# EVE1_VCOP register map
Vendor: Texas Instruments
Peripheral module from a debugger description file (folder DRA75x_DRA74x).
Registers are 32-bit, read-only, reset 0x0 unless marked. A register's access mark holds for its fields unless they carry their own. Offsets are as the file gives them; lines under a group give offsets from that group; [hi:lo] are bit positions; {n}, {i} and the like mark numbered series; 'fields as' and 'values as' point back to an identical list; <NAME> marks a mode.

## EVE1_VCOP
0x00 VCOP_PID
  [31:0] PID — IP Revision
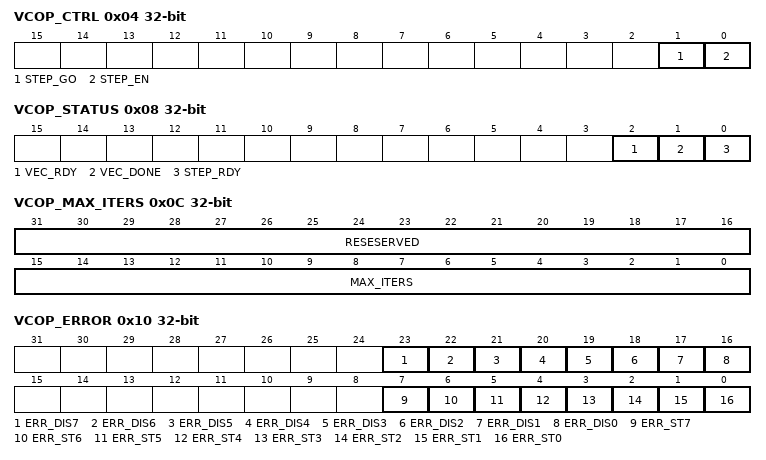
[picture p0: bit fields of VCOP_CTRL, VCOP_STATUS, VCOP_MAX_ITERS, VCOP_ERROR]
0x04 VCOP_CTRL access per field — VCOP Control Register
  [1] STEP_GO rw — Starts executing a single i4 iteration
    0=NOP; 1=START
  [0] STEP_EN rw — Enable Single Step mode
    0=Disable; 1=Enable
0x08 VCOP_STATUS
  [2] VEC_RDY — Vector core ready to accept next vector instruction
  [1] VEC_DONE — Vector core has completed execution of submitted vector loops.
  [0] STEP_RDY — Ready for next step (single step)
    0=Busy; 1=Idle_and_ready_for_next_step
0x0C VCOP_MAX_ITERS access per field
  [31:16] RESESERVED ro — Reserved. Read returns 0s
  [15:0] MAX_ITERS rw — Maximum iteration count. Send interrupt when a loop in execution exceeds the programmed max iteration count. This is to guard against VCOP hangs due to run-away program.
    0=Disable_(default); 1=Enable
0x10 VCOP_ERROR rw — Error interrupt enalbe and status register. Writing 1 to the ERR_STi bits clears the interrupt status.
  [23] ERR_DIS7 — Error Interrupt disable.
    0=Enable; 1=Disable_ST_PDDA_bank_conflict
  [22] ERR_DIS6 — Error Interrupt disable.
    0=Enable; 1=Disable_ST_WBUF_out-of-bound
  [21] ERR_DIS5 — Error Interrupt disable.
    0=Enable; 1=Disable_ST_IBUF_out-of-bound
  [20] ERR_DIS4 — Error Interrupt disable.
    0=Enable; 1=Disable_LD_WBUF_out-of-bound
  [19] ERR_DIS3 — Error Interrupt disable.
    0=Enable; 1=Disable_LD_IBUF_out-of-bound
  [18] ERR_DIS2 — Error Interrupt disable.
    0=Enable; 1=Disable Illegal parameter (pointer not 32-bit aligned, pointer out-of-bound, exceed max repeat count)
  [17] ERR_DIS1 — Error Interrupt disable.
    0=Enable; 1=Disable Illegal instruction, all other causes than inside-loop instructions detected outside loop
  [16] ERR_DIS0 — Error Interrupt disable.
    0=Enable; 1=VADD)_VCOP_PC_ARP32_PC_VLOOP_1 (Disable Illegal instruction; inside-loop instructions (eg, VADD) detected outside loop.When this occurs, the decode value is indeterminate, since VCOP expects valid PC on vec_paddr bus, and ARP32 only sends PC with valid VLOOP instruction.)
  [7] ERR_ST7 — ST_PDDA bank conflict error status:
    0=No_error; 1=Error
  [6] ERR_ST6 — ST WBUF out-of-bound error status:
    0=No_error; 1=Error
  [5] ERR_ST5 — ST IBUF out-of-bound error status:
    0=No_error; 1=Error
  [4] ERR_ST4 — LD WBUF out-of-bound error status:
    0=No_error; 1=Error
  [3] ERR_ST3 — LD IBUF out-of-bound error status:
    0=No_error; 1=Error
  [2] ERR_ST2 — Illegal parameter error status. Effected when pointer is not 32-bit aligned, pointer is outof- bound, or exceed max repeat count.
    0=No_error; 1=Error
  [1] ERR_ST1 — Illegal instruction error status. Effected by all other causes than inside-loop instructions detected outside loop.
    0=No_error; 1=Error
  [0] ERR_ST0 — Illegal instruction error status. Effected by inside-loop instructions (eg, VADD) detected outside loop. When this occurs, VCOP_VLOOP_PTR_DEC value is indeterminate, since VCOP expects valid PC on vec_paddr bus, and ARP32 only sends PC with valid VLOOP instruction.
    0=No_error; 1=Error
0x20 VCOP_VLOOP_PTR — The VLOOP pointer
  [31:0] VLOOP_PTR — VLOOP pointer.
0x24 VCOP_PARAM_PTR
  [31:0] PARAM_PTR — Points to the beginning of parameter block for the loop in execution.
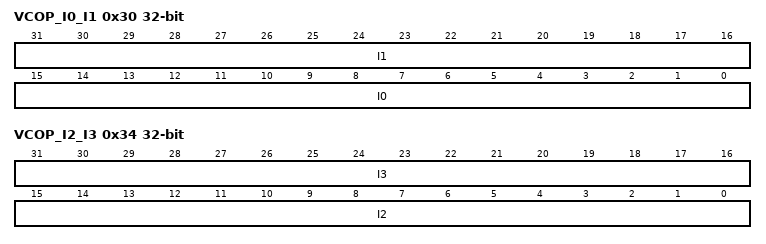
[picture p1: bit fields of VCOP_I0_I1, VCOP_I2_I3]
0x30 VCOP_I0_I1 — I0, I1 loop variables register provides a snapshot of i0 and i1
  [31:16] I1 — Snapshot of I1 loop variable.
  [15:0] I0 — Snapshot of I0 loop variable.
0x34 VCOP_I2_I3 — I2, I3 loop variables register provides a snapshot of i2 and i3
  [31:16] I3 — Snapshot of I2 loop variable.
  [15:0] I2 — Snapshot of I3 loop variable.
0x38 VCOP_I4 — I4 loop variables register provides a snapshot of i4
  [15:0] I4 — Snapshot of I4 loop variable.
{0x40+4i} VCOP_LD_PTR_i_{i} (i=0..7) — The LD pointer registers 0 to 7 or (VCOP_LD_PTR(0..7)) is a snapshot of the LD memory address. The LD unit is identified by the destination vector register V0..V7
  [31:0] LD_PTRi — LD pointer i (i = 0 to 7).
{0x60+4i} VCOP_ST_PTR_j_{i} (i=0..7) — The ST pointer registers 0 to 7 (VCOP_VLOOP_ST_PTR(0..7)) is a snapshot of the ST memory address. The ST unit is identified by the order ST appears in program.
  [31:0] ST_PTR0 — ST pointer j (j=0 to 7).
